# CY8C5888LTI_LP097 register map
File version: 0.1
CY8C58LP
Registers are 8-bit, read-write, no defined reset value unless marked. A register's access mark holds for its fields unless they carry their own. Offsets are from the block's base; lines under a group give offsets from that group; [hi:lo] are bit positions; {n}, {i} and the like mark numbered series; 'fields as' and 'values as' point back to an identical list; <NAME> marks a mode.

## Memory map
0x4000646A via8bits2_P1_stat
0x4000646B via8bits1_P1_stat
0x4000646C via8bits1_Stat
0x4000646D via8bits1_P0_stat
0x4000646E via8bits2_Stat
0x4000646F via8bits2_P0_stat
0x4000647A via8bits2_P1_ctrl
0x4000647B via8bits1_P1_ctrl
0x4000647C via8bits1_Ctrl
0x4000647D via8bits1_P0_ctrl
0x4000647E via8bits2_Ctrl
0x4000647F via8bits2_P0_ctrl

## via8bits2_P1_stat
Base 0x4000646A
0x00 via8bits2_P1_stat_STATUS_REG
0x20 via8bits2_P1_stat_MASK_REG
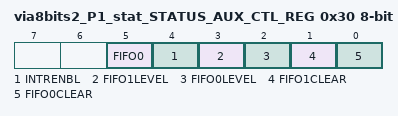
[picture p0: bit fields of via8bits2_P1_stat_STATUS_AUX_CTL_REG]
0x30 via8bits2_P1_stat_STATUS_AUX_CTL_REG
  [5] FIFO0 — FIFO0 clear
    1=ENABLED (Enable counter); 0=DISABLED (Disable counter)
  [4] INTRENBL — Enables or disables the Interrupt
    1=ENABLED (Interrupt enabled); 0=DISABLED (Interrupt disabled)
  [3] FIFO1LEVEL — FIFO level
    1=ENABLED (FIFO LVL: input mode: FIFO at least 1/2 empty; output mode: FIFO at least 1/2 full); 0=DISABLED (FIFO LVL: input mode: FIFO not full; output mode: FIFO not empty)
  [2] FIFO0LEVEL — FIFO level
    values as FIFO1LEVEL
  [1] FIFO1CLEAR — FIFO clear
    1=ENABLED (Clear FIFO state); 0=DISABLED (Normal FIFO operation)
  [0] FIFO0CLEAR — FIFO clear
    values as FIFO1CLEAR

## via8bits2_Stat
Base 0x4000646E
Registers as via8bits2_P1_stat (with via8bits2_P1_stat read as via8bits2_Stat).

## via8bits2_Ctrl
Base 0x4000647E
0x00 via8bits2_Ctrl_CONTROL_REG

## via8bits2_P0_ctrl
Base 0x4000647F
Registers as via8bits2_Ctrl (with via8bits2_Ctrl read as via8bits2_P0_ctrl).

## via8bits2_P1_ctrl
Base 0x4000647A
Registers as via8bits2_Ctrl (with via8bits2_Ctrl read as via8bits2_P1_ctrl).

## via8bits2_P0_stat
Base 0x4000646F
Registers as via8bits2_P1_stat (with via8bits2_P1_stat read as via8bits2_P0_stat).

## via8bits1_P1_stat
Base 0x4000646B
Registers as via8bits2_P1_stat (with via8bits2_P1_stat read as via8bits1_P1_stat).

## via8bits1_Stat
Base 0x4000646C
Registers as via8bits2_P1_stat (with via8bits2_P1_stat read as via8bits1_Stat).

## via8bits1_Ctrl
Base 0x4000647C
Registers as via8bits2_Ctrl (with via8bits2_Ctrl read as via8bits1_Ctrl).

## via8bits1_P0_ctrl
Base 0x4000647D
Registers as via8bits2_Ctrl (with via8bits2_Ctrl read as via8bits1_P0_ctrl).

## via8bits1_P1_ctrl
Base 0x4000647B
Registers as via8bits2_Ctrl (with via8bits2_Ctrl read as via8bits1_P1_ctrl).

## via8bits1_P0_stat
Base 0x4000646D
Registers as via8bits2_P1_stat (with via8bits2_P1_stat read as via8bits1_P0_stat).
